VERSION ""

NS_ :

BS_:

BU_: Host Bootloader Application

BO_ 1792 Bootloader_Response: 8 Bootloader
 SG_ ResponseType : 0|8@1+ (1,0) [0|255] ""  Host
 SG_ ErrorCode : 8|8@1+ (1,0) [0|255] ""  Host
 SG_ State : 16|8@1+ (1,0) [0|255] ""  Host
 SG_ BytesWritten : 24|32@1+ (1,0) [0|4294967295] "bytes"  Host
 SG_ DataByte0 : 8|8@1+ (1,0) [0|255] ""  Host
 SG_ DataByte1 : 16|8@1+ (1,0) [0|255] ""  Host
 SG_ DataByte2 : 24|8@1+ (1,0) [0|255] ""  Host
 SG_ DataByte3 : 32|8@1+ (1,0) [0|255] ""  Host
 SG_ DataByte4 : 40|8@1+ (1,0) [0|255] ""  Host
 SG_ DataByte5 : 48|8@1+ (1,0) [0|255] ""  Host
 SG_ DataByte6 : 56|8@1+ (1,0) [0|255] ""  Host

CM_ BO_ 1792 "Bootloader response messages to host PC. Contains ACK/NACK, status, data, and error information.";
CM_ SG_ 1792 ResponseType "Type of response: ACK(0x10), NACK(0x11), ERROR(0x12), BUSY(0x13), READY(0x14), DATA(0x15), JUMP_INFO(0x16)";
CM_ SG_ 1792 ErrorCode "Error code when ResponseType is NACK or ERROR. 0x00=no error";
CM_ SG_ 1792 State "Current bootloader state: IDLE(0), ERASING(1), WRITING(2), READING(3), VERIFYING(4), JUMPING(5)";
CM_ SG_ 1792 BytesWritten "Total bytes written to application flash area (for STATUS response)";
CM_ SG_ 1792 DataByte0 "Generic data byte 0 for DATA or READ_FLASH responses";
CM_ SG_ 1792 DataByte1 "Generic data byte 1 for DATA or READ_FLASH responses";
CM_ SG_ 1792 DataByte2 "Generic data byte 2 for DATA or READ_FLASH responses";
CM_ SG_ 1792 DataByte3 "Generic data byte 3 for DATA or READ_FLASH responses";
CM_ SG_ 1792 DataByte4 "Generic data byte 4 for DATA or READ_FLASH responses";
CM_ SG_ 1792 DataByte5 "Generic data byte 5 for DATA or READ_FLASH responses";
CM_ SG_ 1792 DataByte6 "Generic data byte 6 for DATA or READ_FLASH responses";

VAL_ 1792 ResponseType 16 "ACK" 17 "NACK" 18 "ERROR" 19 "BUSY" 20 "READY" 21 "DATA" 22 "JUMP_INFO" ;
VAL_ 1792 ErrorCode 0 "ERR_NONE" 1 "ERR_INVALID_COMMAND" 2 "ERR_INVALID_ADDRESS" 3 "ERR_FLASH_ERASE_FAILED" 4 "ERR_FLASH_WRITE_FAILED" 5 "ERR_INVALID_DATA_LENGTH" 6 "ERR_NO_VALID_APP" 7 "ERR_TIMEOUT" ;
VAL_ 1792 State 0 "IDLE" 1 "ERASING" 2 "WRITING" 3 "READING" 4 "VERIFYING" 5 "JUMPING" ;

BO_ 1793 Host_Command: 8 Host
 SG_ CommandType : 0|8@1+ (1,0) [0|255] ""  Bootloader
 SG_ Address : 8|32@1+ (1,0) [0|4294967295] ""  Bootloader
 SG_ DataLength : 40|8@1+ (1,0) [0|255] "bytes"  Bootloader
 SG_ DataByte0 : 48|8@1+ (1,0) [0|255] ""  Bootloader
 SG_ DataByte1 : 56|8@1+ (1,0) [0|255] ""  Bootloader
 SG_ DataByte2 : 48|8@1+ (1,0) [0|255] ""  Bootloader
 SG_ DataByte3 : 56|8@1+ (1,0) [0|255] ""  Bootloader

CM_ BO_ 1793 "Host command messages to bootloader for firmware update operations";
CM_ SG_ 1793 CommandType "Command from host: ERASE(1), WRITE_FLASH(2), READ_FLASH(3), JUMP(4), STATUS(5), SET_ADDR(6), WRITE_DATA(7)";
CM_ SG_ 1793 Address "32-bit flash memory address for read/write/set operations. Application area: 0x08008000-0x0803FFFF";
CM_ SG_ 1793 DataLength "Number of bytes for WRITE_FLASH(legacy) or READ_FLASH commands. Modern WRITE_DATA uses fixed 4-byte chunks";
CM_ SG_ 1793 DataByte0 "Data byte 0 for WRITE_DATA command (sends 4 bytes per message)";
CM_ SG_ 1793 DataByte1 "Data byte 1 for WRITE_DATA command";
CM_ SG_ 1793 DataByte2 "Data byte 2 for WRITE_DATA command";
CM_ SG_ 1793 DataByte3 "Data byte 3 for WRITE_DATA command";

VAL_ 1793 CommandType 1 "CMD_ERASE_FLASH" 2 "CMD_WRITE_FLASH" 3 "CMD_READ_FLASH" 4 "CMD_JUMP_TO_APP" 5 "CMD_GET_STATUS" 6 "CMD_SET_ADDRESS" 7 "CMD_WRITE_DATA" ;

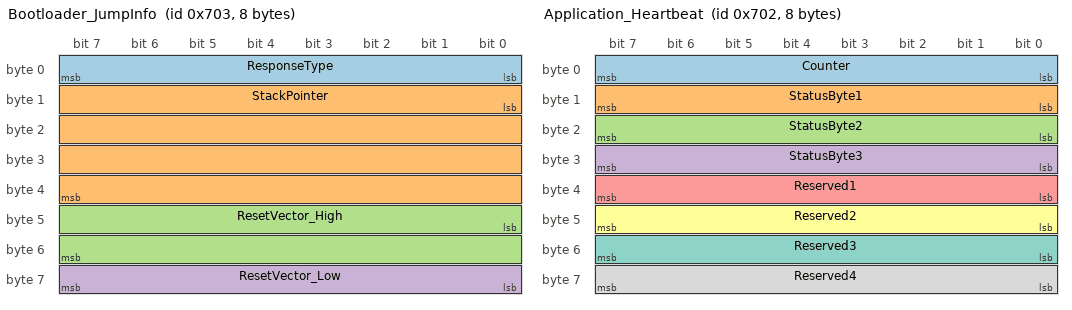
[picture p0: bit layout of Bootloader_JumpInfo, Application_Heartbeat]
BO_ 1795 Bootloader_JumpInfo: 8 Bootloader
 SG_ ResponseType : 0|8@1+ (1,0) [0|255] ""  Host
 SG_ StackPointer : 8|32@1+ (1,0) [0|4294967295] ""  Host
 SG_ ResetVector_High : 40|16@1+ (1,0) [0|65535] ""  Host
 SG_ ResetVector_Low : 56|8@1+ (1,0) [0|255] ""  Host

CM_ BO_ 1795 "Detailed jump to application diagnostics (sent immediately before jumping to application code)";
CM_ SG_ 1795 ResponseType "Always RESP_JUMP_INFO (0x16) for this message";
CM_ SG_ 1795 StackPointer "Application initial stack pointer from vector table at 0x08008000. Should be 0x2000xxxx (valid RAM address)";
CM_ SG_ 1795 ResetVector_High "Application reset handler address bits [23:8]. Combined with ResetVector_Low gives full address";
CM_ SG_ 1795 ResetVector_Low "Application reset handler address bits [7:0]. LSB should be 1 (Thumb mode). Full address should be 0x0800xxxx";

BO_ 1794 Application_Heartbeat: 8 Application
 SG_ Counter : 0|8@1+ (1,0) [0|255] ""  Host,Bootloader
 SG_ StatusByte1 : 8|8@1+ (1,0) [0|255] ""  Host,Bootloader
 SG_ StatusByte2 : 16|8@1+ (1,0) [0|255] ""  Host,Bootloader
 SG_ StatusByte3 : 24|8@1+ (1,0) [0|255] ""  Host,Bootloader
 SG_ Reserved1 : 32|8@1+ (1,0) [0|255] ""  Host,Bootloader
 SG_ Reserved2 : 40|8@1+ (1,0) [0|255] ""  Host,Bootloader
 SG_ Reserved3 : 48|8@1+ (1,0) [0|255] ""  Host,Bootloader
 SG_ Reserved4 : 56|8@1+ (1,0) [0|255] ""  Host,Bootloader

CM_ BO_ 1794 "Application heartbeat message sent every 10 seconds when application is running. Indicates successful jump from bootloader.";
CM_ SG_ 1794 Counter "Heartbeat counter, increments with each message (rolls over at 255)";
CM_ SG_ 1794 StatusByte1 "Status byte 1: Always 0x55 (signature)";
CM_ SG_ 1794 StatusByte2 "Status byte 2: Always 0x01 (message type)";
CM_ SG_ 1794 StatusByte3 "Status byte 3: Reserved";
CM_ SG_ 1794 Reserved1 "Reserved for future use (application state, error flags, etc.)";
CM_ SG_ 1794 Reserved2 "Reserved for future use";
CM_ SG_ 1794 Reserved3 "Reserved for future use";
CM_ SG_ 1794 Reserved4 "Reserved for future use";

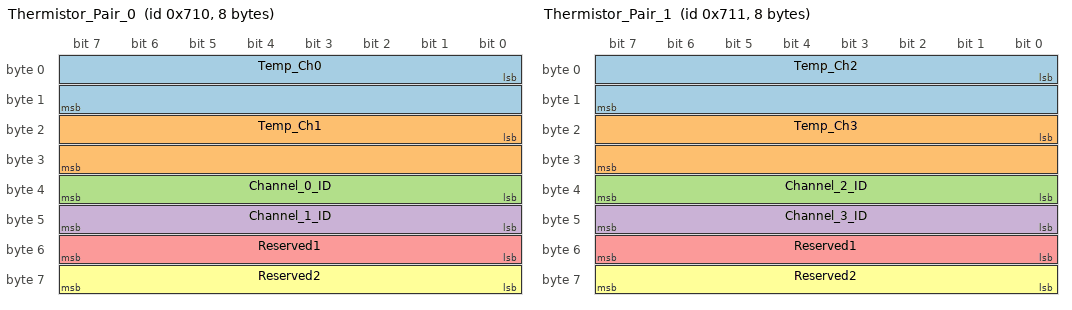
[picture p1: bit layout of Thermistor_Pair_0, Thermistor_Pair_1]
BO_ 1808 Thermistor_Pair_0: 8 Application
 SG_ Temp_Ch0 : 0|16@1- (0.01,0) [-400|1250] "degC"  Host
 SG_ Temp_Ch1 : 16|16@1- (0.01,0) [-400|1250] "degC"  Host
 SG_ Channel_0_ID : 32|8@1+ (1,0) [0|7] ""  Host
 SG_ Channel_1_ID : 40|8@1+ (1,0) [0|7] ""  Host
 SG_ Reserved1 : 48|8@1+ (1,0) [0|255] ""  Host
 SG_ Reserved2 : 56|8@1+ (1,0) [0|255] ""  Host

CM_ BO_ 1808 "Thermistor pair 0: Channels 0 and 1 temperature readings (sent every 1 second)";
CM_ SG_ 1808 Temp_Ch0 "Temperature from thermistor channel 0 (multiply raw value by 0.01 to get degrees C)";
CM_ SG_ 1808 Temp_Ch1 "Temperature from thermistor channel 1 (multiply raw value by 0.01 to get degrees C)";
CM_ SG_ 1808 Channel_0_ID "Always 0 - identifies first thermistor channel in this message";
CM_ SG_ 1808 Channel_1_ID "Always 1 - identifies second thermistor channel in this message";
CM_ SG_ 1808 Reserved1 "Reserved for future use";
CM_ SG_ 1808 Reserved2 "Reserved for future use";

BO_ 1809 Thermistor_Pair_1: 8 Application
 SG_ Temp_Ch2 : 0|16@1- (0.01,0) [-400|1250] "degC"  Host
 SG_ Temp_Ch3 : 16|16@1- (0.01,0) [-400|1250] "degC"  Host
 SG_ Channel_2_ID : 32|8@1+ (1,0) [0|7] ""  Host
 SG_ Channel_3_ID : 40|8@1+ (1,0) [0|7] ""  Host
 SG_ Reserved1 : 48|8@1+ (1,0) [0|255] ""  Host
 SG_ Reserved2 : 56|8@1+ (1,0) [0|255] ""  Host

CM_ BO_ 1809 "Thermistor pair 1: Channels 2 and 3 temperature readings (sent every 1 second)";
CM_ SG_ 1809 Temp_Ch2 "Temperature from thermistor channel 2 (multiply raw value by 0.01 to get degrees C)";
CM_ SG_ 1809 Temp_Ch3 "Temperature from thermistor channel 3 (multiply raw value by 0.01 to get degrees C)";
CM_ SG_ 1809 Channel_2_ID "Always 2 - identifies first thermistor channel in this message";
CM_ SG_ 1809 Channel_3_ID "Always 3 - identifies second thermistor channel in this message";
CM_ SG_ 1809 Reserved1 "Reserved for future use";
CM_ SG_ 1809 Reserved2 "Reserved for future use";

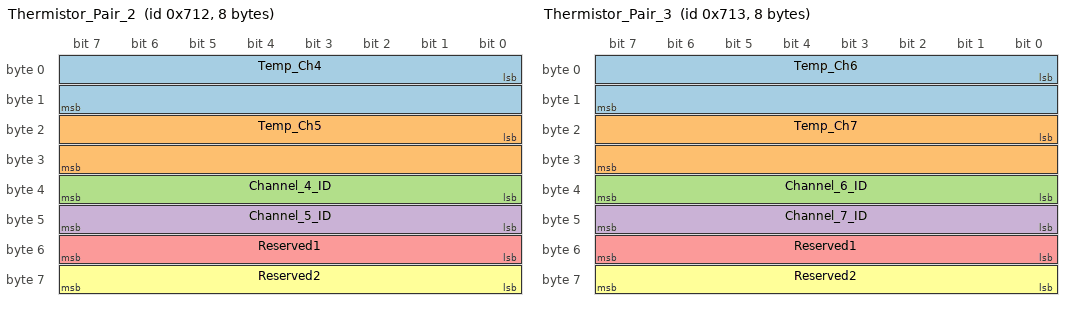
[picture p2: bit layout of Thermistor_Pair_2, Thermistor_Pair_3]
BO_ 1810 Thermistor_Pair_2: 8 Application
 SG_ Temp_Ch4 : 0|16@1- (0.01,0) [-400|1250] "degC"  Host
 SG_ Temp_Ch5 : 16|16@1- (0.01,0) [-400|1250] "degC"  Host
 SG_ Channel_4_ID : 32|8@1+ (1,0) [0|7] ""  Host
 SG_ Channel_5_ID : 40|8@1+ (1,0) [0|7] ""  Host
 SG_ Reserved1 : 48|8@1+ (1,0) [0|255] ""  Host
 SG_ Reserved2 : 56|8@1+ (1,0) [0|255] ""  Host

CM_ BO_ 1810 "Thermistor pair 2: Channels 4 and 5 temperature readings (sent every 1 second)";
CM_ SG_ 1810 Temp_Ch4 "Temperature from thermistor channel 4 (multiply raw value by 0.01 to get degrees C)";
CM_ SG_ 1810 Temp_Ch5 "Temperature from thermistor channel 5 (multiply raw value by 0.01 to get degrees C)";
CM_ SG_ 1810 Channel_4_ID "Always 4 - identifies first thermistor channel in this message";
CM_ SG_ 1810 Channel_5_ID "Always 5 - identifies second thermistor channel in this message";
CM_ SG_ 1810 Reserved1 "Reserved for future use";
CM_ SG_ 1810 Reserved2 "Reserved for future use";

BO_ 1811 Thermistor_Pair_3: 8 Application
 SG_ Temp_Ch6 : 0|16@1- (0.01,0) [-400|1250] "degC"  Host
 SG_ Temp_Ch7 : 16|16@1- (0.01,0) [-400|1250] "degC"  Host
 SG_ Channel_6_ID : 32|8@1+ (1,0) [0|7] ""  Host
 SG_ Channel_7_ID : 40|8@1+ (1,0) [0|7] ""  Host
 SG_ Reserved1 : 48|8@1+ (1,0) [0|255] ""  Host
 SG_ Reserved2 : 56|8@1+ (1,0) [0|255] ""  Host

CM_ BO_ 1811 "Thermistor pair 3: Channels 6 and 7 temperature readings (sent every 1 second)";
CM_ SG_ 1811 Temp_Ch6 "Temperature from thermistor channel 6 (multiply raw value by 0.01 to get degrees C)";
CM_ SG_ 1811 Temp_Ch7 "Temperature from thermistor channel 7 (multiply raw value by 0.01 to get degrees C)";
CM_ SG_ 1811 Channel_6_ID "Always 6 - identifies first thermistor channel in this message";
CM_ SG_ 1811 Channel_7_ID "Always 7 - identifies second thermistor channel in this message";
CM_ SG_ 1811 Reserved1 "Reserved for future use";
CM_ SG_ 1811 Reserved2 "Reserved for future use";

BA_DEF_ "BusType" STRING ;
BA_DEF_ BO_ "GenMsgCycleTime" INT 0 10000;
BA_DEF_ BO_ "GenMsgSendType" STRING ;

BA_DEF_DEF_ "BusType" "CAN";
BA_DEF_DEF_ "GenMsgCycleTime" 0;
BA_DEF_DEF_ "GenMsgSendType" "event";

BA_ "GenMsgCycleTime" BO_ 1794 10000;
BA_ "GenMsgCycleTime" BO_ 1808 1000;
BA_ "GenMsgCycleTime" BO_ 1809 1000;
BA_ "GenMsgCycleTime" BO_ 1810 1000;
BA_ "GenMsgCycleTime" BO_ 1811 1000;
BA_ "GenMsgSendType" BO_ 1794 "cyclic";
BA_ "GenMsgSendType" BO_ 1808 "cyclic";
BA_ "GenMsgSendType" BO_ 1809 "cyclic";
BA_ "GenMsgSendType" BO_ 1810 "cyclic";
BA_ "GenMsgSendType" BO_ 1811 "cyclic";
